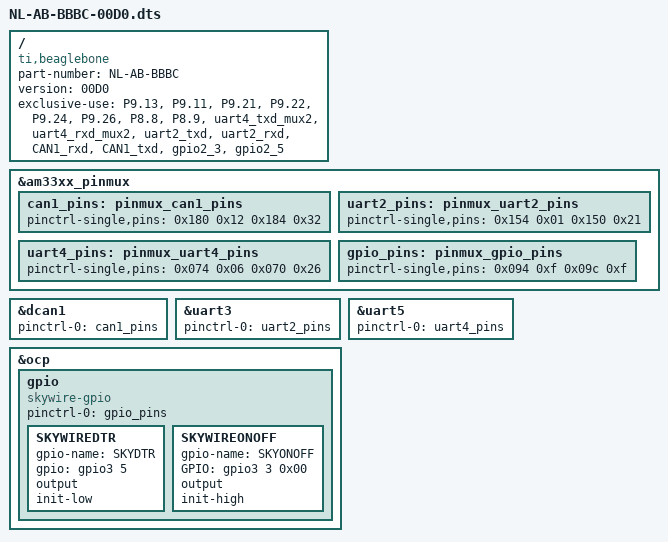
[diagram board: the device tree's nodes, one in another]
/*
* Copyright (C) 2014 Nimbelink, Corp <product.support@nimbelink.com>
*
* This program is free software; you can redistribute it and/or modify
* it under the terms of the GNU General Public License version 2 as
* published by the Free Software Foundation.
*
* This is a device tree overlay file for Nimbelinks Skywire Beaglebone Black Cape.
* This code initializes CAN1, UART2, UART4, and GPIOs P8.8 and P8.9 for use with the capes default operating mode.
* This overlay file was developed from referencing the projectM device tree files (https://github.com/gntoni/projectM/tree/master/devTree)
* and from the embedded things.com CANBUS tutorial (http://www.embedded-things.com/bbb/enable-canbus-on-the-beaglebone-black/)
*
*/

/dts-v1/;
/plugin/;

/{
	compatible = "ti,beaglebone", "ti,beaglebone-black";
	part-number = "NL-AB-BBBC";
	version = "00D0";

	/* State resources this cape uses */
	exclusive-use =
		/* the pin header and pins used */
		"P9.13", /* UART4 TXD */
		"P9.11", /* UART4 RXD */
		"P9.21", /* UART2 TXD */
		"P9.22", /* UART2 RXD */
		"P9.24", /* CAN1 RXD */
		"P9.26", /* CAN1 TXD */
		"P8.8", /*SKYWIRE ON-OFF*/
		"P8.9", /*SKYWIRE DTR*/

		 /* the hardware IP use */
		"uart4_txd_mux2",
		"uart4_rxd_mux2",
		"uart2_txd",
		"uart2_rxd",
		"CAN1_rxd",
		"CAN1_txd",
		"gpio2_3",
		"gpio2_5";

	/*Mux the Pins */

	fragment@0 {
		target = <&am33xx_pinmux>;
		__overlay__ {
			/*CONFIGURE CAN1*/
			can1_pins: pinmux_can1_pins {
				pinctrl-single,pins = <
					0x180 0x12  /* d_can1_tx, SLEWCTRL_FAST | INPUT_PULLUP | MODE2 */
					0x184 0x32  /* d_can1_rx, SLEWCTRL_FAST | RECV_ENABLE | INPUT_PULLUP | MODE2 */
					>;
			};
			/*CONFIGURE UART2*/
			uart2_pins: pinmux_uart2_pins {
				pinctrl-single,pins = <
					0x154 0x01 /* P9_24 = GPIO0_15 = spi0_d0.uart2_txd, OUTPUT */
					0x150 0x21 /* P9_26 = GPIO0_14 = spi0_sclk.uart2_rxd, INPUT */
					>;
			};
			/*CONFIGRE UART4*/
			uart4_pins: pinmux_uart4_pins {
				pinctrl-single,pins = <
					0x074 0x06 /* P9_13 = GPIO0_31 = gpmc_wpn.uart4_txd_mux2, OUTPUT */
					0x070 0x26 /* P9_11 = GPIO0_30 = gpmc_wait0.uart4_rxd_mux2, INPUT */
					>;
			/*CONFIGURE GPIO*/
			};
			gpio_pins: pinmux_gpio_pins{
				pinctrl-single,pins = <
					0x094 0xf		/* P8.8, gpio2_3, SLEWCTRL_FAST | PULLUP_DISABLED | MODE7*/
					0x09c 0xf		/* P9.9, gpio2_5, SLEWCTRL_FAST | PULLUP_DISABLED | MODE7*/
					>;
			};
		};
	};

/*=============Enable the device ==================*/

/*============Connect the device to user interface driver ==============*/
/*To connect the device with a user interface,
/*specify the â€œcompatibleâ€ field in the â€œocpâ€ section.
/*ocp stand for On Chip Peripherals,
/*BTW. The compatible field should match the driver you want to use.*/


	/*Turn on CAN1*/
	fragment@1 {
		target = <&dcan1>;
		__overlay__ {
			#address-cells = <1>;
			#size-cells = <0>;

			status = "okay";
			pinctrl-names = "default";
			pinctrl-0 = <&can1_pins>;
		};
	};

	/*Turn on UART2*/
	fragment@2 {
		target = <&uart3>; /* really uart2 */
		__overlay__ {
			pinctrl-names = "default";
			pinctrl-0 = <&uart2_pins>;
			status = "okay";
		};
	};

	/*Turn on UART4*/
	fragment@3 {
		target = <&uart5>; /* really uart4 */
		__overlay__ {
			pinctrl-names = "default";
			pinctrl-0 = <&uart4_pins>;
			status = "okay";
		};
	};

	/*Turn on GPIO*/
	fragment@4 {
		target = <&ocp>;
		__overlay__ {
			#address-cells = <1>;
			#size-cells = <1>;
			gpio {
				compatible = "skywire-gpio";
				status 	= "okay";
				pinctrl-names   = "default";
				pinctrl-0       = <&gpio_pins>;

				/*declare the gpios*/
				SKYWIREDTR {
					gpio-name = "SKYDTR";
					gpio = <&gpio3 5 0x00>; /*GPIO3 is GPIO2*/
					output;
					init-low;
				};

				SKYWIREONOFF {
					gpio-name = "SKYONOFF";
					GPIO = <&gpio3 3 0x00>;
					output;
					init-high;
				};
			};
		};
	};
};
